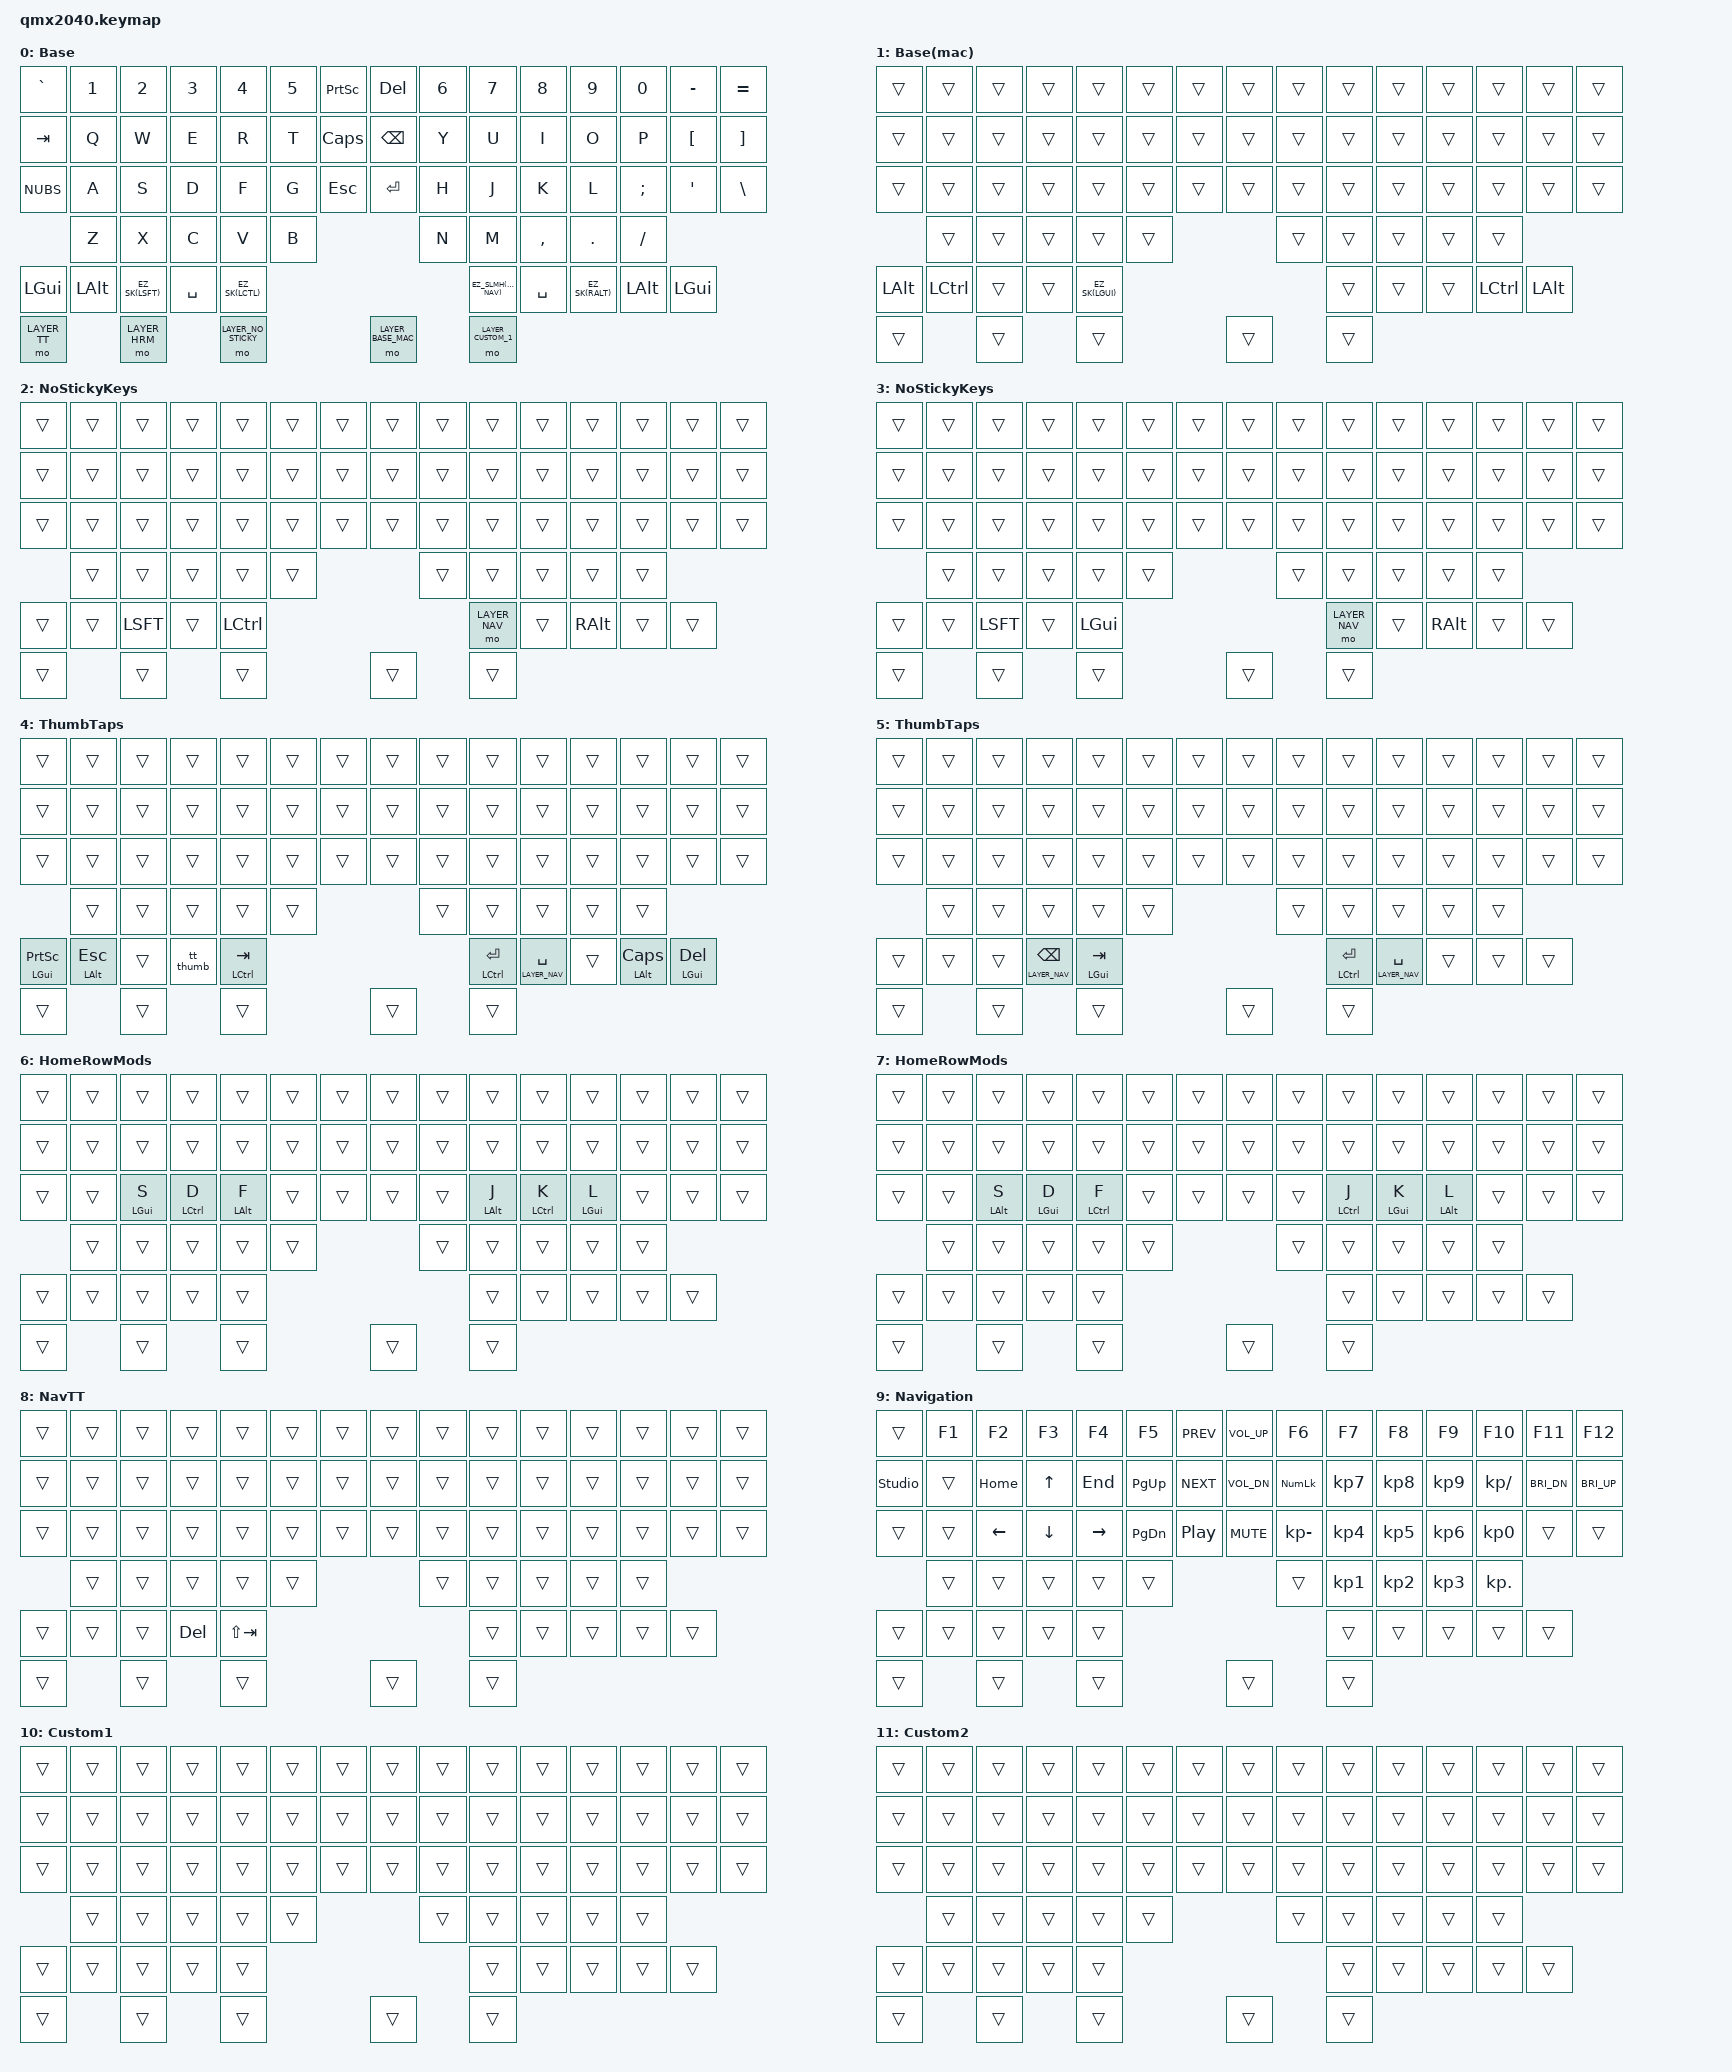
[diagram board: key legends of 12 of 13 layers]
#include <behaviors.dtsi>
#include <dt-bindings/zmk/keys.h>

// Timing is key
#define TAPPING_TERM       300
#define SHORT_TAPPING_TERM 150
#define QUICK_TAP          200

// Human-readable layer indexes
#define LAYER_BASE          0
#define LAYER_BASE_MAC      1
#define LAYER_NO_STICKY     2
#define LAYER_NO_STICKY_MAC 3
#define LAYER_TT            4
#define LAYER_TT_MAC        5
#define LAYER_HRM           6
#define LAYER_HRM_MAC       7
#define LAYER_NAV_TT        8
#define LAYER_NAV           9
#define LAYER_CUSTOM_1     10
#define LAYER_CUSTOM_2     11
#define LAYER_CUSTOM_3     12

// HRM Shorthands
#define HRM_S &hrm LGUI S
#define HRM_D &hrm LCTL D
#define HRM_F &hrm LALT F
#define HRM_J &hrm LALT J
#define HRM_K &hrm LCTL K
#define HRM_L &hrm LGUI L

// HRM Shorthands (mac)
#define MHRM_S &hrm LALT S
#define MHRM_D &hrm LGUI D
#define MHRM_F &hrm LCTL F
#define MHRM_J &hrm LCTL J
#define MHRM_K &hrm LGUI K
#define MHRM_L &hrm LALT L

#define EZ_SL(layer)    bsl   (layer) (layer)
#define EZ_SLMH(layer)  bslmh (layer) (layer)
#define EZ_SK(mod)      bsk   (mod) (mod)

&sl { ignore-modifiers; }; // keep one-shot-mods when chained into a one-shot-layer
&sk { quick-release; };    // must-have! (lots of false positives otherwise)

// add our common tap-hold parametesr to the default options
&mt {
  tapping-term-ms = <SHORT_TAPPING_TERM>;
  quick-tap-ms = <QUICK_TAP>;
};

&lt {
  tapping-term-ms = <TAPPING_TERM>;
  quick-tap-ms = <QUICK_TAP>;
};

/ {
  behaviors {
    hrm: homerow_mods {
      compatible = "zmk,behavior-hold-tap";
      #binding-cells = <2>;
      tapping-term-ms = <TAPPING_TERM>;
      quick-tap-ms = <QUICK_TAP>;
      flavor = "tap-preferred";
      bindings = <&kp>, <&kp>;
    };
    sc: space_cadet { // same as lt, but with hold-preferred
      compatible = "zmk,behavior-hold-tap";
      #binding-cells = <2>;
      tapping-term-ms = <SHORT_TAPPING_TERM>;
      quick-tap-ms = <QUICK_TAP>;
      flavor = "hold-preferred";
      bindings = <&mo>, <&kp>;
    };
    // like ZMK's sticky layer (sl) but with a more robust timing
    osl: one_shot_layer {
      compatible = "zmk,behavior-macro-one-param";
      #binding-cells = <1>;
      tap-ms = <0>;
      wait-ms = <0>;
      bindings = <&macro_param_1to1>, <&macro_tap &sl MACRO_PLACEHOLDER>;
    };
    bsl: better_sticky_layer {
      compatible = "zmk,behavior-hold-tap";
      #binding-cells = <2>;
      tapping-term-ms = <TAPPING_TERM>;
      flavor = "tap-preferred";
      bindings = <&mo>, <&osl>;
    };
    // like ZMK's sticky key (sk) but with a more robust timing
    osm: one_shot_modifier {
      compatible = "zmk,behavior-macro-one-param";
      #binding-cells = <1>;
      tap-ms = <0>;
      wait-ms = <0>;
      bindings = <&macro_param_1to1>, <&macro_tap &sk MACRO_PLACEHOLDER>;
    };
    bsk: better_sticky_key {
      compatible = "zmk,behavior-hold-tap";
      #binding-cells = <2>;
      tapping-term-ms = <TAPPING_TERM>;
      flavor = "tap-preferred";
      bindings = <&kp>, <&osm>;
    };

    // mod-holds
    bslmh: better_sticky_layer_with_held_mods {
      compatible = "zmk,behavior-mod-hold";
      #binding-cells = <2>;
      binding = <&bsl>;
      mods-to-hold = <0xff>;  // every possible modifier
    };

    tt_thumb: tt_thumb {
      compatible = "zmk,behavior-mod-morph";
      #binding-cells = <0>;
      bindings  = <&sc LAYER_NAV BSPC>, <&lt LAYER_NAV SPC>;
      mods      = <MOD_RALT>;
      keep-mods = <MOD_RALT>;
    };
  };

  conditional_layers {
    compatible = "zmk,conditional-layers";

    nav_tt {
      if-layers = <LAYER_TT LAYER_NAV>;
      then-layer = <LAYER_NAV_TT>;
    };

    mac_no_sticky {
      if-layers = <LAYER_BASE_MAC LAYER_NO_STICKY>;
      then-layer = <LAYER_NO_STICKY_MAC>;
    };

    mac_tt {
      if-layers = <LAYER_BASE_MAC LAYER_TT>;
      then-layer = <LAYER_TT_MAC>;
    };

    mac_hrm {
      if-layers = <LAYER_BASE_MAC LAYER_HRM>;
      then-layer = <LAYER_HRM_MAC>;
    };

  };

  keymap {
    compatible = "zmk,keymap";

    base_layer: base_layer {
      display-name = "Base";
      bindings = <
        &kp GRAVE &kp N1 &kp N2 &kp N3 &kp N4 &kp N5 &kp PSCRN   &kp DEL   &kp N6 &kp N7 &kp N8    &kp N9  &kp N0   &kp MINUS &kp EQUAL
        &kp TAB   &kp Q  &kp W  &kp E  &kp R  &kp T  &kp CAPS    &kp BSPC  &kp Y  &kp U  &kp I     &kp O   &kp P    &kp LBKT  &kp RBKT
        &kp NUBS  &kp A  &kp S  &kp D  &kp F  &kp G  &kp ESC     &kp ENTER &kp H  &kp J  &kp K     &kp L   &kp SEMI &kp SQT   &kp BSLH
                  &kp Z  &kp X  &kp C  &kp V  &kp B                        &kp N  &kp M  &kp COMMA &kp DOT &kp FSLH
           &kp LGUI &kp LALT &EZ_SK(LSFT) &kp SPC &EZ_SK(LCTL)   &EZ_SLMH(LAYER_NAV) &kp SPC &EZ_SK(RALT) &kp LALT &kp LGUI
           &mo LAYER_TT  &mo LAYER_HRM  &mo LAYER_NO_STICKY  &mo LAYER_BASE_MAC  &mo LAYER_CUSTOM_1
      >;
    };

    mac_base_layer: mac_base_layer {
      display-name = "Base(mac)";
      bindings = <
        &trans &trans &trans &trans &trans &trans &trans &trans &trans &trans &trans &trans &trans &trans &trans
        &trans &trans &trans &trans &trans &trans &trans &trans &trans &trans &trans &trans &trans &trans &trans
        &trans &trans &trans &trans &trans &trans &trans &trans &trans &trans &trans &trans &trans &trans &trans
               &trans &trans &trans &trans &trans               &trans &trans &trans &trans &trans
          &kp LALT &kp LCTL &trans &trans &EZ_SK(LGUI)       &trans &trans &trans &kp LCTL &kp LALT
          &trans  &trans  &trans  &trans  &trans
      >;
    };

    no_sticky_layer: no_sticky_layer {
      display-name = "NoStickyKeys";
      bindings = <
        &trans &trans &trans &trans &trans &trans &trans &trans &trans &trans &trans &trans &trans &trans &trans
        &trans &trans &trans &trans &trans &trans &trans &trans &trans &trans &trans &trans &trans &trans &trans
        &trans &trans &trans &trans &trans &trans &trans &trans &trans &trans &trans &trans &trans &trans &trans
               &trans &trans &trans &trans &trans               &trans &trans &trans &trans &trans
               &trans &trans &kp LSFT &trans &kp LCTL    &mo LAYER_NAV &trans &kp RALT &trans &trans
          &trans  &trans  &trans  &trans  &trans
      >;
    };

    mac_no_sticky_layer: mac_no_sticky_layer {
      display-name = "NoStickyKeys";
      bindings = <
        &trans &trans &trans &trans &trans &trans &trans &trans &trans &trans &trans &trans &trans &trans &trans
        &trans &trans &trans &trans &trans &trans &trans &trans &trans &trans &trans &trans &trans &trans &trans
        &trans &trans &trans &trans &trans &trans &trans &trans &trans &trans &trans &trans &trans &trans &trans
               &trans &trans &trans &trans &trans               &trans &trans &trans &trans &trans
               &trans &trans &kp LSFT &trans &kp LGUI    &mo LAYER_NAV &trans &kp RALT &trans &trans
          &trans  &trans  &trans  &trans  &trans
      >;
    };

    thumb_taps_layer: thumb_taps_layer {
      display-name = "ThumbTaps";
      bindings = <
        &trans &trans &trans &trans &trans &trans &trans &trans &trans &trans &trans &trans &trans &trans &trans
        &trans &trans &trans &trans &trans &trans &trans &trans &trans &trans &trans &trans &trans &trans &trans
        &trans &trans &trans &trans &trans &trans &trans &trans &trans &trans &trans &trans &trans &trans &trans
               &trans &trans &trans &trans &trans                         &trans &trans &trans &trans &trans
        &mt LGUI PSCRN &mt LALT ESC &trans &tt_thumb &mt LCTL TAB      &mt LCTL ENTER &lt LAYER_NAV SPC &trans &mt LALT CAPS &mt LGUI DEL
          &trans  &trans  &trans  &trans  &trans
      >;
    };

    mac_thumb_taps_layer: mac_thumb_taps_layer {
      display-name = "ThumbTaps";
      bindings = <
        &trans &trans &trans &trans &trans &trans &trans &trans &trans &trans &trans &trans &trans &trans &trans
        &trans &trans &trans &trans &trans &trans &trans &trans &trans &trans &trans &trans &trans &trans &trans
        &trans &trans &trans &trans &trans &trans &trans &trans &trans &trans &trans &trans &trans &trans &trans
               &trans &trans &trans &trans &trans               &trans &trans &trans &trans &trans
               &trans &trans &trans &sc LAYER_NAV BSPC &mt LGUI TAB         &mt LCTL ENTER &lt LAYER_NAV SPC &trans &trans &trans
          &trans  &trans  &trans  &trans  &trans
      >;
    };

    hrm_layer: hrm_layer {
      display-name = "HomeRowMods";
      bindings = <
        &trans &trans &trans &trans &trans &trans &trans &trans &trans &trans &trans &trans &trans &trans &trans
        &trans &trans &trans &trans &trans &trans &trans &trans &trans &trans &trans &trans &trans &trans &trans
        &trans &trans HRM_S  HRM_D  HRM_F  &trans &trans &trans &trans HRM_J  HRM_K  HRM_L  &trans &trans &trans
               &trans &trans &trans &trans &trans               &trans &trans &trans &trans &trans
               &trans &trans &trans &trans &trans               &trans &trans &trans &trans &trans
          &trans  &trans  &trans  &trans  &trans
      >;
    };

    mac_hrm_layer: mac_hrm_layer {
      display-name = "HomeRowMods";
      bindings = <
        &trans &trans &trans &trans &trans &trans &trans &trans &trans &trans &trans &trans &trans &trans &trans
        &trans &trans &trans &trans &trans &trans &trans &trans &trans &trans &trans &trans &trans &trans &trans
        &trans &trans MHRM_S MHRM_D MHRM_F &trans &trans &trans &trans MHRM_J MHRM_K MHRM_L &trans &trans &trans
               &trans &trans &trans &trans &trans               &trans &trans &trans &trans &trans
               &trans &trans &trans &trans &trans               &trans &trans &trans &trans &trans
          &trans  &trans  &trans  &trans  &trans
      >;
    };

    nav_tt_layer: nav_tt_layer {
      display-name = "NavTT";
      bindings = <
        &trans &trans &trans &trans &trans &trans &trans &trans &trans &trans &trans &trans &trans &trans &trans
        &trans &trans &trans &trans &trans &trans &trans &trans &trans &trans &trans &trans &trans &trans &trans
        &trans &trans &trans &trans &trans &trans &trans &trans &trans &trans &trans &trans &trans &trans &trans
               &trans &trans &trans &trans &trans               &trans &trans &trans &trans &trans
               &trans &trans &trans &kp DEL &kp LS(TAB)         &trans &trans &trans &trans &trans
          &trans  &trans  &trans  &trans  &trans
      >;
    };

    navigation_layer: navigation_layer {
      display-name = "Navigation";
      bindings = <
        &trans         &kp F1  &kp F2   &kp F3   &kp F4    &kp F5    &kp C_PREV &kp C_VOL_UP &kp F6       &kp F7    &kp F8    &kp F9    &kp F10      &kp F11      &kp F12
        &studio_unlock &trans  &kp HOME &kp UP   &kp END   &kp PG_UP &kp C_NEXT &kp C_VOL_DN &kp KP_NUM   &kp KP_N7 &kp KP_N8 &kp KP_N9 &kp KP_SLASH &kp C_BRI_DN &kp C_BRI_UP
        &trans         &trans  &kp LEFT &kp DOWN &kp RIGHT &kp PG_DN &kp C_PP   &kp C_MUTE   &kp KP_MINUS &kp KP_N4 &kp KP_N5 &kp KP_N6 &kp KP_N0    &trans       &trans
                       &trans  &trans   &trans   &trans    &trans                            &trans       &kp KP_N1 &kp KP_N2 &kp KP_N3 &kp KP_DOT
                       &trans  &trans   &trans   &trans    &trans                            &trans       &trans &trans &trans &trans
          &trans  &trans  &trans  &trans  &trans
      >;
    };

    custom_layer_1: custom_layer_1 {
      display-name = "Custom1";
      bindings = <
        &trans &trans &trans &trans &trans &trans &trans &trans &trans &trans &trans &trans &trans &trans &trans
        &trans &trans &trans &trans &trans &trans &trans &trans &trans &trans &trans &trans &trans &trans &trans
        &trans &trans &trans &trans &trans &trans &trans &trans &trans &trans &trans &trans &trans &trans &trans
               &trans &trans &trans &trans &trans               &trans &trans &trans &trans &trans
               &trans &trans &trans &trans &trans               &trans &trans &trans &trans &trans
          &trans  &trans  &trans  &trans  &trans
      >;
    };

    custom_layer_2: custom_layer_2 {
      display-name = "Custom2";
      bindings = <
        &trans &trans &trans &trans &trans &trans &trans &trans &trans &trans &trans &trans &trans &trans &trans
        &trans &trans &trans &trans &trans &trans &trans &trans &trans &trans &trans &trans &trans &trans &trans
        &trans &trans &trans &trans &trans &trans &trans &trans &trans &trans &trans &trans &trans &trans &trans
               &trans &trans &trans &trans &trans               &trans &trans &trans &trans &trans
               &trans &trans &trans &trans &trans               &trans &trans &trans &trans &trans
          &trans  &trans  &trans  &trans  &trans
      >;
    };

    custom_layer_3: custom_layer_3 {
      display-name = "Custom3";
      bindings = <
        &trans &trans &trans &trans &trans &trans &trans &trans &trans &trans &trans &trans &trans &trans &trans
        &trans &trans &trans &trans &trans &trans &trans &trans &trans &trans &trans &trans &trans &trans &trans
        &trans &trans &trans &trans &trans &trans &trans &trans &trans &trans &trans &trans &trans &trans &trans
               &trans &trans &trans &trans &trans               &trans &trans &trans &trans &trans
               &trans &trans &trans &trans &trans               &trans &trans &trans &trans &trans
          &trans  &trans  &trans  &trans  &trans
      >;
    };

  };
};
